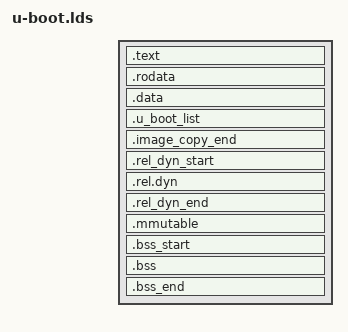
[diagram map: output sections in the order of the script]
OUTPUT_FORMAT("elf32-littlearm", "elf32-littlearm", "elf32-littlearm")
OUTPUT_ARCH(arm)
ENTRY(_start)
SECTIONS
{
 . = 0x00000000;
 . = ALIGN(4);
 .text :
 {
  *(.__image_copy_start)
  arch/arm/cpu/armv7/start.o (.text*)
  board/knobloch/TXT/libTXT.o (.text*)
  *(.text*)
 }
 . = ALIGN(4);
 .rodata : { *(SORT_BY_ALIGNMENT(SORT_BY_NAME(.rodata*))) }
 . = ALIGN(4);
 .data : {
  *(.data*)
 }
 . = ALIGN(4);
 . = .;
 . = ALIGN(4);
 .u_boot_list : {
  KEEP(*(SORT(.u_boot_list*)));
 }
 . = ALIGN(4);
 .image_copy_end :
 {
  *(.__image_copy_end)
 }
 .rel_dyn_start :
 {
  *(.__rel_dyn_start)
 }
 .rel.dyn : {
  *(.rel*)
 }
 .rel_dyn_end :
 {
  *(.__rel_dyn_end)
 }
 _end = .;
 . = ALIGN(4096);
 .mmutable : {
  *(.mmutable)
 }
 .bss_start __rel_dyn_start (OVERLAY) : {
  KEEP(*(.__bss_start));
  __bss_base = .;
 }
 .bss __bss_base (OVERLAY) : {
  *(.bss*)
   . = ALIGN(4);
   __bss_limit = .;
 }
 .bss_end __bss_limit (OVERLAY) : {
  KEEP(*(.__bss_end));
 }
 /DISCARD/ : { *(.dynsym) }
 /DISCARD/ : { *(.dynstr*) }
 /DISCARD/ : { *(.dynamic*) }
 /DISCARD/ : { *(.plt*) }
 /DISCARD/ : { *(.interp*) }
 /DISCARD/ : { *(.gnu*) }
}
